AUTOSAR XML (schema 00050)
package /MICROSAR/NvM_swc/DataTypes
  impl type NvM_RequestResultType: compu {0=NVM_REQ_OK, 1=NVM_REQ_NOT_OK, 2=NVM_REQ_PENDING, 3=NVM_REQ_INTEGRITY_FAILED, 4=NVM_REQ_BLOCK_SKIPPED, 5=NVM_REQ_NV_INVALIDATED, 6=NVM_REQ_CANCELED, 7=NVM_REQ_REDUNDANCY_FAILED, 8=NVM_REQ_RESTORED_FROM_ROM}, range raw 0..8, implementation-data-type=uint8
  impl type NvM_BlockIdType: range raw 1..32767, implementation-data-type=uint16
package /MICROSAR/NvM_swc/Interfaces
  client server interface NvMAdministration: is-service=true, service-kind=NON-VOLATILE-RAM-MANAGER
    operation SetBlockProtection: possible-error=NvMAdministration/E_NOT_OK
      arg ProtectionEnabled: type=boolean, direction=IN
    error E_NOT_OK: error-code=1
  client server interface NvMService_AC3_SRBS: is-service=true, service-kind=NON-VOLATILE-RAM-MANAGER
    6 x operation, all with possible-error=NvMService_AC3_SRBS/E_NOT_OK:
      GetErrorStatus
        arg ErrorStatus: type=NvM_RequestResultType, direction=OUT
      SetRamBlockStatus
        arg RamBlockStatus: type=boolean, direction=IN
      ReadBlock
        arg DstPtr: type=dtRef_VOID, direction=IN
      WriteBlock
        arg SrcPtr: type=dtRef_const_VOID, direction=IN
      InvalidateNvBlock
      EraseBlock
    error E_NOT_OK: error-code=1
package /MICROSAR/NvM_swc/ComponentTypes
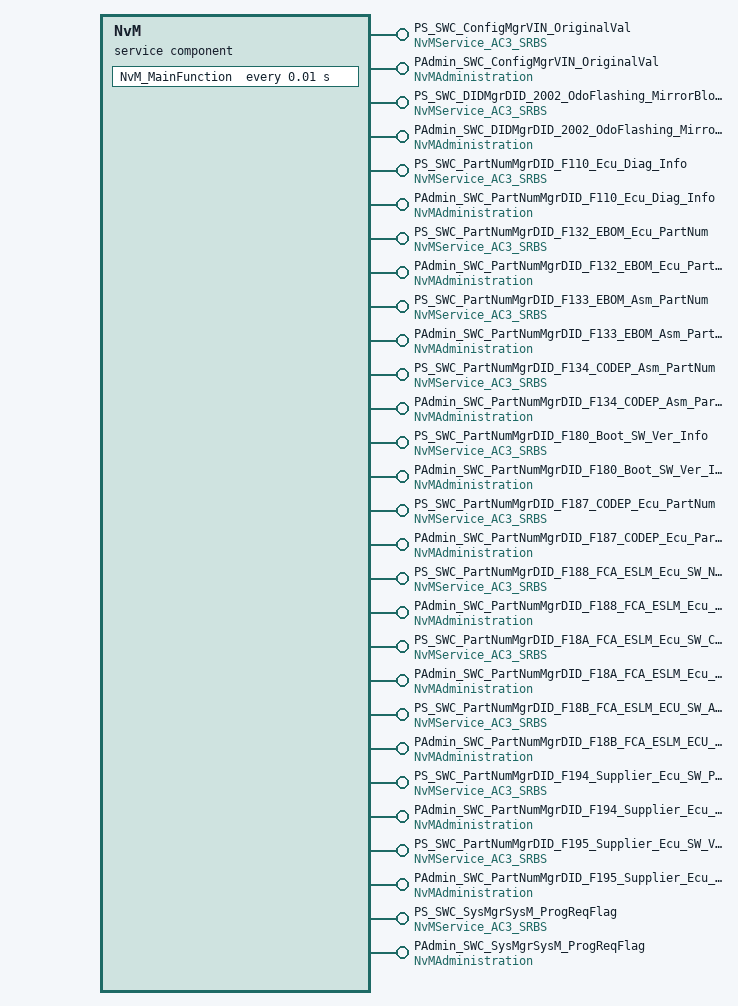
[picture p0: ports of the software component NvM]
  service sw component type NvM: category=SERVICE_COMPONENT
    28 x provide port:
      PS_SWC_ConfigMgrVIN_OriginalVal: provided-interface=NvMService_AC3_SRBS
      PAdmin_SWC_ConfigMgrVIN_OriginalVal: provided-interface=NvMAdministration
      PS_SWC_DIDMgrDID_2002_OdoFlashing_MirrorBlock: provided-interface=NvMService_AC3_SRBS
      PAdmin_SWC_DIDMgrDID_2002_OdoFlashing_MirrorBlock: provided-interface=NvMAdministration
      PS_SWC_PartNumMgrDID_F110_Ecu_Diag_Info: provided-interface=NvMService_AC3_SRBS
      PAdmin_SWC_PartNumMgrDID_F110_Ecu_Diag_Info: provided-interface=NvMAdministration
      PS_SWC_PartNumMgrDID_F132_EBOM_Ecu_PartNum: provided-interface=NvMService_AC3_SRBS
      PAdmin_SWC_PartNumMgrDID_F132_EBOM_Ecu_PartNum: provided-interface=NvMAdministration
      PS_SWC_PartNumMgrDID_F133_EBOM_Asm_PartNum: provided-interface=NvMService_AC3_SRBS
      PAdmin_SWC_PartNumMgrDID_F133_EBOM_Asm_PartNum: provided-interface=NvMAdministration
      PS_SWC_PartNumMgrDID_F134_CODEP_Asm_PartNum: provided-interface=NvMService_AC3_SRBS
      PAdmin_SWC_PartNumMgrDID_F134_CODEP_Asm_PartNum: provided-interface=NvMAdministration
      PS_SWC_PartNumMgrDID_F180_Boot_SW_Ver_Info: provided-interface=NvMService_AC3_SRBS
      PAdmin_SWC_PartNumMgrDID_F180_Boot_SW_Ver_Info: provided-interface=NvMAdministration
      PS_SWC_PartNumMgrDID_F187_CODEP_Ecu_PartNum: provided-interface=NvMService_AC3_SRBS
      PAdmin_SWC_PartNumMgrDID_F187_CODEP_Ecu_PartNum: provided-interface=NvMAdministration
      PS_SWC_PartNumMgrDID_F188_FCA_ESLM_Ecu_SW_Num: provided-interface=NvMService_AC3_SRBS
      PAdmin_SWC_PartNumMgrDID_F188_FCA_ESLM_Ecu_SW_Num: provided-interface=NvMAdministration
      PS_SWC_PartNumMgrDID_F18A_FCA_ESLM_Ecu_SW_Cal_Num: provided-interface=NvMService_AC3_SRBS
      PAdmin_SWC_PartNumMgrDID_F18A_FCA_ESLM_Ecu_SW_Cal_Num: provided-interface=NvMAdministration
      PS_SWC_PartNumMgrDID_F18B_FCA_ESLM_ECU_SW_App_Num: provided-interface=NvMService_AC3_SRBS
      PAdmin_SWC_PartNumMgrDID_F18B_FCA_ESLM_ECU_SW_App_Num: provided-interface=NvMAdministration
      PS_SWC_PartNumMgrDID_F194_Supplier_Ecu_SW_PartNum: provided-interface=NvMService_AC3_SRBS
      PAdmin_SWC_PartNumMgrDID_F194_Supplier_Ecu_SW_PartNum: provided-interface=NvMAdministration
      PS_SWC_PartNumMgrDID_F195_Supplier_Ecu_SW_VerNum: provided-interface=NvMService_AC3_SRBS
      PAdmin_SWC_PartNumMgrDID_F195_Supplier_Ecu_SW_VerNum: provided-interface=NvMAdministration
      PS_SWC_SysMgrSysM_ProgReqFlag: provided-interface=NvMService_AC3_SRBS
      PAdmin_SWC_SysMgrSysM_ProgReqFlag: provided-interface=NvMAdministration
    behavior NvMInternalBehavior: handle-termination-and-restart=NO-SUPPORT
      timing event Timer_NvM_MainFunction: start-on-event=NvM_MainFunction, period=0.01
      98 x operation invoked event:
        OpEventGetErrorStatus_GetErrorStatus_PS_SWC_ConfigMgrVIN_OriginalVal: start-on-event=GetErrorStatus, operation=PS_SWC_ConfigMgrVIN_OriginalVal.GetErrorStatus
        OpEventGetErrorStatus_GetErrorStatus_PS_SWC_DIDMgrDID_2002_OdoFlashing_MirrorBlock: start-on-event=GetErrorStatus, operation=PS_SWC_DIDMgrDID_2002_OdoFlashing_MirrorBlock.GetErrorStatus
        OpEventGetErrorStatus_GetErrorStatus_PS_SWC_PartNumMgrDID_F110_Ecu_Diag_Info: start-on-event=GetErrorStatus, operation=PS_SWC_PartNumMgrDID_F110_Ecu_Diag_Info.GetErrorStatus
        OpEventGetErrorStatus_GetErrorStatus_PS_SWC_PartNumMgrDID_F132_EBOM_Ecu_PartNum: start-on-event=GetErrorStatus, operation=PS_SWC_PartNumMgrDID_F132_EBOM_Ecu_PartNum.GetErrorStatus
        OpEventGetErrorStatus_GetErrorStatus_PS_SWC_PartNumMgrDID_F133_EBOM_Asm_PartNum: start-on-event=GetErrorStatus, operation=PS_SWC_PartNumMgrDID_F133_EBOM_Asm_PartNum.GetErrorStatus
        OpEventGetErrorStatus_GetErrorStatus_PS_SWC_PartNumMgrDID_F134_CODEP_Asm_PartNum: start-on-event=GetErrorStatus, operation=PS_SWC_PartNumMgrDID_F134_CODEP_Asm_PartNum.GetErrorStatus
        OpEventGetErrorStatus_GetErrorStatus_PS_SWC_PartNumMgrDID_F180_Boot_SW_Ver_Info: start-on-event=GetErrorStatus, operation=PS_SWC_PartNumMgrDID_F180_Boot_SW_Ver_Info.GetErrorStatus
        OpEventGetErrorStatus_GetErrorStatus_PS_SWC_PartNumMgrDID_F187_CODEP_Ecu_PartNum: start-on-event=GetErrorStatus, operation=PS_SWC_PartNumMgrDID_F187_CODEP_Ecu_PartNum.GetErrorStatus
        OpEventGetErrorStatus_GetErrorStatus_PS_SWC_PartNumMgrDID_F188_FCA_ESLM_Ecu_SW_Num: start-on-event=GetErrorStatus, operation=PS_SWC_PartNumMgrDID_F188_FCA_ESLM_Ecu_SW_Num.GetErrorStatus
        OpEventGetErrorStatus_GetErrorStatus_PS_SWC_PartNumMgrDID_F18A_FCA_ESLM_Ecu_SW_Cal_Num: start-on-event=GetErrorStatus, operation=PS_SWC_PartNumMgrDID_F18A_FCA_ESLM_Ecu_SW_Cal_Num.GetErrorStatus
        OpEventGetErrorStatus_GetErrorStatus_PS_SWC_PartNumMgrDID_F18B_FCA_ESLM_ECU_SW_App_Num: start-on-event=GetErrorStatus, operation=PS_SWC_PartNumMgrDID_F18B_FCA_ESLM_ECU_SW_App_Num.GetErrorStatus
        OpEventGetErrorStatus_GetErrorStatus_PS_SWC_PartNumMgrDID_F194_Supplier_Ecu_SW_PartNum: start-on-event=GetErrorStatus, operation=PS_SWC_PartNumMgrDID_F194_Supplier_Ecu_SW_PartNum.GetErrorStatus
        OpEventGetErrorStatus_GetErrorStatus_PS_SWC_PartNumMgrDID_F195_Supplier_Ecu_SW_VerNum: start-on-event=GetErrorStatus, operation=PS_SWC_PartNumMgrDID_F195_Supplier_Ecu_SW_VerNum.GetErrorStatus
        OpEventGetErrorStatus_GetErrorStatus_PS_SWC_SysMgrSysM_ProgReqFlag: start-on-event=GetErrorStatus, operation=PS_SWC_SysMgrSysM_ProgReqFlag.GetErrorStatus
        OpEventSetRamBlockStatus_SetRamBlockStatus_PS_SWC_ConfigMgrVIN_OriginalVal: start-on-event=SetRamBlockStatus, operation=PS_SWC_ConfigMgrVIN_OriginalVal.SetRamBlockStatus
        OpEventSetRamBlockStatus_SetRamBlockStatus_PS_SWC_DIDMgrDID_2002_OdoFlashing_MirrorBlock: start-on-event=SetRamBlockStatus, operation=PS_SWC_DIDMgrDID_2002_OdoFlashing_MirrorBlock.SetRamBlockStatus
        OpEventSetRamBlockStatus_SetRamBlockStatus_PS_SWC_PartNumMgrDID_F110_Ecu_Diag_Info: start-on-event=SetRamBlockStatus, operation=PS_SWC_PartNumMgrDID_F110_Ecu_Diag_Info.SetRamBlockStatus
        OpEventSetRamBlockStatus_SetRamBlockStatus_PS_SWC_PartNumMgrDID_F132_EBOM_Ecu_PartNum: start-on-event=SetRamBlockStatus, operation=PS_SWC_PartNumMgrDID_F132_EBOM_Ecu_PartNum.SetRamBlockStatus
        OpEventSetRamBlockStatus_SetRamBlockStatus_PS_SWC_PartNumMgrDID_F133_EBOM_Asm_PartNum: start-on-event=SetRamBlockStatus, operation=PS_SWC_PartNumMgrDID_F133_EBOM_Asm_PartNum.SetRamBlockStatus
        OpEventSetRamBlockStatus_SetRamBlockStatus_PS_SWC_PartNumMgrDID_F134_CODEP_Asm_PartNum: start-on-event=SetRamBlockStatus, operation=PS_SWC_PartNumMgrDID_F134_CODEP_Asm_PartNum.SetRamBlockStatus
        OpEventSetRamBlockStatus_SetRamBlockStatus_PS_SWC_PartNumMgrDID_F180_Boot_SW_Ver_Info: start-on-event=SetRamBlockStatus, operation=PS_SWC_PartNumMgrDID_F180_Boot_SW_Ver_Info.SetRamBlockStatus
        OpEventSetRamBlockStatus_SetRamBlockStatus_PS_SWC_PartNumMgrDID_F187_CODEP_Ecu_PartNum: start-on-event=SetRamBlockStatus, operation=PS_SWC_PartNumMgrDID_F187_CODEP_Ecu_PartNum.SetRamBlockStatus
        OpEventSetRamBlockStatus_SetRamBlockStatus_PS_SWC_PartNumMgrDID_F188_FCA_ESLM_Ecu_SW_Num: start-on-event=SetRamBlockStatus, operation=PS_SWC_PartNumMgrDID_F188_FCA_ESLM_Ecu_SW_Num.SetRamBlockStatus
        OpEventSetRamBlockStatus_SetRamBlockStatus_PS_SWC_PartNumMgrDID_F18A_FCA_ESLM_Ecu_SW_Cal_Num: start-on-event=SetRamBlockStatus, operation=PS_SWC_PartNumMgrDID_F18A_FCA_ESLM_Ecu_SW_Cal_Num.SetRamBlockStatus
        OpEventSetRamBlockStatus_SetRamBlockStatus_PS_SWC_PartNumMgrDID_F18B_FCA_ESLM_ECU_SW_App_Num: start-on-event=SetRamBlockStatus, operation=PS_SWC_PartNumMgrDID_F18B_FCA_ESLM_ECU_SW_App_Num.SetRamBlockStatus
        OpEventSetRamBlockStatus_SetRamBlockStatus_PS_SWC_PartNumMgrDID_F194_Supplier_Ecu_SW_PartNum: start-on-event=SetRamBlockStatus, operation=PS_SWC_PartNumMgrDID_F194_Supplier_Ecu_SW_PartNum.SetRamBlockStatus
        OpEventSetRamBlockStatus_SetRamBlockStatus_PS_SWC_PartNumMgrDID_F195_Supplier_Ecu_SW_VerNum: start-on-event=SetRamBlockStatus, operation=PS_SWC_PartNumMgrDID_F195_Supplier_Ecu_SW_VerNum.SetRamBlockStatus
        OpEventSetRamBlockStatus_SetRamBlockStatus_PS_SWC_SysMgrSysM_ProgReqFlag: start-on-event=SetRamBlockStatus, operation=PS_SWC_SysMgrSysM_ProgReqFlag.SetRamBlockStatus
        OpEventReadBlock_ReadBlock_PS_SWC_ConfigMgrVIN_OriginalVal: start-on-event=ReadBlock, operation=PS_SWC_ConfigMgrVIN_OriginalVal.ReadBlock
        OpEventReadBlock_ReadBlock_PS_SWC_DIDMgrDID_2002_OdoFlashing_MirrorBlock: start-on-event=ReadBlock, operation=PS_SWC_DIDMgrDID_2002_OdoFlashing_MirrorBlock.ReadBlock
        OpEventReadBlock_ReadBlock_PS_SWC_PartNumMgrDID_F110_Ecu_Diag_Info: start-on-event=ReadBlock, operation=PS_SWC_PartNumMgrDID_F110_Ecu_Diag_Info.ReadBlock
        OpEventReadBlock_ReadBlock_PS_SWC_PartNumMgrDID_F132_EBOM_Ecu_PartNum: start-on-event=ReadBlock, operation=PS_SWC_PartNumMgrDID_F132_EBOM_Ecu_PartNum.ReadBlock
        OpEventReadBlock_ReadBlock_PS_SWC_PartNumMgrDID_F133_EBOM_Asm_PartNum: start-on-event=ReadBlock, operation=PS_SWC_PartNumMgrDID_F133_EBOM_Asm_PartNum.ReadBlock
        OpEventReadBlock_ReadBlock_PS_SWC_PartNumMgrDID_F134_CODEP_Asm_PartNum: start-on-event=ReadBlock, operation=PS_SWC_PartNumMgrDID_F134_CODEP_Asm_PartNum.ReadBlock
        OpEventReadBlock_ReadBlock_PS_SWC_PartNumMgrDID_F180_Boot_SW_Ver_Info: start-on-event=ReadBlock, operation=PS_SWC_PartNumMgrDID_F180_Boot_SW_Ver_Info.ReadBlock
        OpEventReadBlock_ReadBlock_PS_SWC_PartNumMgrDID_F187_CODEP_Ecu_PartNum: start-on-event=ReadBlock, operation=PS_SWC_PartNumMgrDID_F187_CODEP_Ecu_PartNum.ReadBlock
        OpEventReadBlock_ReadBlock_PS_SWC_PartNumMgrDID_F188_FCA_ESLM_Ecu_SW_Num: start-on-event=ReadBlock, operation=PS_SWC_PartNumMgrDID_F188_FCA_ESLM_Ecu_SW_Num.ReadBlock
        OpEventReadBlock_ReadBlock_PS_SWC_PartNumMgrDID_F18A_FCA_ESLM_Ecu_SW_Cal_Num: start-on-event=ReadBlock, operation=PS_SWC_PartNumMgrDID_F18A_FCA_ESLM_Ecu_SW_Cal_Num.ReadBlock
        OpEventReadBlock_ReadBlock_PS_SWC_PartNumMgrDID_F18B_FCA_ESLM_ECU_SW_App_Num: start-on-event=ReadBlock, operation=PS_SWC_PartNumMgrDID_F18B_FCA_ESLM_ECU_SW_App_Num.ReadBlock
        OpEventReadBlock_ReadBlock_PS_SWC_PartNumMgrDID_F194_Supplier_Ecu_SW_PartNum: start-on-event=ReadBlock, operation=PS_SWC_PartNumMgrDID_F194_Supplier_Ecu_SW_PartNum.ReadBlock
        OpEventReadBlock_ReadBlock_PS_SWC_PartNumMgrDID_F195_Supplier_Ecu_SW_VerNum: start-on-event=ReadBlock, operation=PS_SWC_PartNumMgrDID_F195_Supplier_Ecu_SW_VerNum.ReadBlock
        OpEventReadBlock_ReadBlock_PS_SWC_SysMgrSysM_ProgReqFlag: start-on-event=ReadBlock, operation=PS_SWC_SysMgrSysM_ProgReqFlag.ReadBlock
        OpEventWriteBlock_WriteBlock_PS_SWC_ConfigMgrVIN_OriginalVal: start-on-event=WriteBlock, operation=PS_SWC_ConfigMgrVIN_OriginalVal.WriteBlock
        OpEventWriteBlock_WriteBlock_PS_SWC_DIDMgrDID_2002_OdoFlashing_MirrorBlock: start-on-event=WriteBlock, operation=PS_SWC_DIDMgrDID_2002_OdoFlashing_MirrorBlock.WriteBlock
        OpEventWriteBlock_WriteBlock_PS_SWC_PartNumMgrDID_F110_Ecu_Diag_Info: start-on-event=WriteBlock, operation=PS_SWC_PartNumMgrDID_F110_Ecu_Diag_Info.WriteBlock
        OpEventWriteBlock_WriteBlock_PS_SWC_PartNumMgrDID_F132_EBOM_Ecu_PartNum: start-on-event=WriteBlock, operation=PS_SWC_PartNumMgrDID_F132_EBOM_Ecu_PartNum.WriteBlock
        OpEventWriteBlock_WriteBlock_PS_SWC_PartNumMgrDID_F133_EBOM_Asm_PartNum: start-on-event=WriteBlock, operation=PS_SWC_PartNumMgrDID_F133_EBOM_Asm_PartNum.WriteBlock
        OpEventWriteBlock_WriteBlock_PS_SWC_PartNumMgrDID_F134_CODEP_Asm_PartNum: start-on-event=WriteBlock, operation=PS_SWC_PartNumMgrDID_F134_CODEP_Asm_PartNum.WriteBlock
        OpEventWriteBlock_WriteBlock_PS_SWC_PartNumMgrDID_F180_Boot_SW_Ver_Info: start-on-event=WriteBlock, operation=PS_SWC_PartNumMgrDID_F180_Boot_SW_Ver_Info.WriteBlock
        OpEventWriteBlock_WriteBlock_PS_SWC_PartNumMgrDID_F187_CODEP_Ecu_PartNum: start-on-event=WriteBlock, operation=PS_SWC_PartNumMgrDID_F187_CODEP_Ecu_PartNum.WriteBlock
        OpEventWriteBlock_WriteBlock_PS_SWC_PartNumMgrDID_F188_FCA_ESLM_Ecu_SW_Num: start-on-event=WriteBlock, operation=PS_SWC_PartNumMgrDID_F188_FCA_ESLM_Ecu_SW_Num.WriteBlock
        OpEventWriteBlock_WriteBlock_PS_SWC_PartNumMgrDID_F18A_FCA_ESLM_Ecu_SW_Cal_Num: start-on-event=WriteBlock, operation=PS_SWC_PartNumMgrDID_F18A_FCA_ESLM_Ecu_SW_Cal_Num.WriteBlock
        OpEventWriteBlock_WriteBlock_PS_SWC_PartNumMgrDID_F18B_FCA_ESLM_ECU_SW_App_Num: start-on-event=WriteBlock, operation=PS_SWC_PartNumMgrDID_F18B_FCA_ESLM_ECU_SW_App_Num.WriteBlock
        OpEventWriteBlock_WriteBlock_PS_SWC_PartNumMgrDID_F194_Supplier_Ecu_SW_PartNum: start-on-event=WriteBlock, operation=PS_SWC_PartNumMgrDID_F194_Supplier_Ecu_SW_PartNum.WriteBlock
        OpEventWriteBlock_WriteBlock_PS_SWC_PartNumMgrDID_F195_Supplier_Ecu_SW_VerNum: start-on-event=WriteBlock, operation=PS_SWC_PartNumMgrDID_F195_Supplier_Ecu_SW_VerNum.WriteBlock
        OpEventWriteBlock_WriteBlock_PS_SWC_SysMgrSysM_ProgReqFlag: start-on-event=WriteBlock, operation=PS_SWC_SysMgrSysM_ProgReqFlag.WriteBlock
        OpEventInvalidateNvBlock_InvalidateNvBlock_PS_SWC_ConfigMgrVIN_OriginalVal: start-on-event=InvalidateNvBlock, operation=PS_SWC_ConfigMgrVIN_OriginalVal.InvalidateNvBlock
        OpEventInvalidateNvBlock_InvalidateNvBlock_PS_SWC_DIDMgrDID_2002_OdoFlashing_MirrorBlock: start-on-event=InvalidateNvBlock, operation=PS_SWC_DIDMgrDID_2002_OdoFlashing_MirrorBlock.InvalidateNvBlock
        OpEventInvalidateNvBlock_InvalidateNvBlock_PS_SWC_PartNumMgrDID_F110_Ecu_Diag_Info: start-on-event=InvalidateNvBlock, operation=PS_SWC_PartNumMgrDID_F110_Ecu_Diag_Info.InvalidateNvBlock
        OpEventInvalidateNvBlock_InvalidateNvBlock_PS_SWC_PartNumMgrDID_F132_EBOM_Ecu_PartNum: start-on-event=InvalidateNvBlock, operation=PS_SWC_PartNumMgrDID_F132_EBOM_Ecu_PartNum.InvalidateNvBlock
        OpEventInvalidateNvBlock_InvalidateNvBlock_PS_SWC_PartNumMgrDID_F133_EBOM_Asm_PartNum: start-on-event=InvalidateNvBlock, operation=PS_SWC_PartNumMgrDID_F133_EBOM_Asm_PartNum.InvalidateNvBlock
        OpEventInvalidateNvBlock_InvalidateNvBlock_PS_SWC_PartNumMgrDID_F134_CODEP_Asm_PartNum: start-on-event=InvalidateNvBlock, operation=PS_SWC_PartNumMgrDID_F134_CODEP_Asm_PartNum.InvalidateNvBlock
        OpEventInvalidateNvBlock_InvalidateNvBlock_PS_SWC_PartNumMgrDID_F180_Boot_SW_Ver_Info: start-on-event=InvalidateNvBlock, operation=PS_SWC_PartNumMgrDID_F180_Boot_SW_Ver_Info.InvalidateNvBlock
        OpEventInvalidateNvBlock_InvalidateNvBlock_PS_SWC_PartNumMgrDID_F187_CODEP_Ecu_PartNum: start-on-event=InvalidateNvBlock, operation=PS_SWC_PartNumMgrDID_F187_CODEP_Ecu_PartNum.InvalidateNvBlock
        OpEventInvalidateNvBlock_InvalidateNvBlock_PS_SWC_PartNumMgrDID_F188_FCA_ESLM_Ecu_SW_Num: start-on-event=InvalidateNvBlock, operation=PS_SWC_PartNumMgrDID_F188_FCA_ESLM_Ecu_SW_Num.InvalidateNvBlock
        OpEventInvalidateNvBlock_InvalidateNvBlock_PS_SWC_PartNumMgrDID_F18A_FCA_ESLM_Ecu_SW_Cal_Num: start-on-event=InvalidateNvBlock, operation=PS_SWC_PartNumMgrDID_F18A_FCA_ESLM_Ecu_SW_Cal_Num.InvalidateNvBlock
        OpEventInvalidateNvBlock_InvalidateNvBlock_PS_SWC_PartNumMgrDID_F18B_FCA_ESLM_ECU_SW_App_Num: start-on-event=InvalidateNvBlock, operation=PS_SWC_PartNumMgrDID_F18B_FCA_ESLM_ECU_SW_App_Num.InvalidateNvBlock
        OpEventInvalidateNvBlock_InvalidateNvBlock_PS_SWC_PartNumMgrDID_F194_Supplier_Ecu_SW_PartNum: start-on-event=InvalidateNvBlock, operation=PS_SWC_PartNumMgrDID_F194_Supplier_Ecu_SW_PartNum.InvalidateNvBlock
        OpEventInvalidateNvBlock_InvalidateNvBlock_PS_SWC_PartNumMgrDID_F195_Supplier_Ecu_SW_VerNum: start-on-event=InvalidateNvBlock, operation=PS_SWC_PartNumMgrDID_F195_Supplier_Ecu_SW_VerNum.InvalidateNvBlock
        OpEventInvalidateNvBlock_InvalidateNvBlock_PS_SWC_SysMgrSysM_ProgReqFlag: start-on-event=InvalidateNvBlock, operation=PS_SWC_SysMgrSysM_ProgReqFlag.InvalidateNvBlock
        OpEventEraseBlock_EraseBlock_PS_SWC_ConfigMgrVIN_OriginalVal: start-on-event=EraseBlock, operation=PS_SWC_ConfigMgrVIN_OriginalVal.EraseBlock
        OpEventEraseBlock_EraseBlock_PS_SWC_DIDMgrDID_2002_OdoFlashing_MirrorBlock: start-on-event=EraseBlock, operation=PS_SWC_DIDMgrDID_2002_OdoFlashing_MirrorBlock.EraseBlock
        OpEventEraseBlock_EraseBlock_PS_SWC_PartNumMgrDID_F110_Ecu_Diag_Info: start-on-event=EraseBlock, operation=PS_SWC_PartNumMgrDID_F110_Ecu_Diag_Info.EraseBlock
        OpEventEraseBlock_EraseBlock_PS_SWC_PartNumMgrDID_F132_EBOM_Ecu_PartNum: start-on-event=EraseBlock, operation=PS_SWC_PartNumMgrDID_F132_EBOM_Ecu_PartNum.EraseBlock
        OpEventEraseBlock_EraseBlock_PS_SWC_PartNumMgrDID_F133_EBOM_Asm_PartNum: start-on-event=EraseBlock, operation=PS_SWC_PartNumMgrDID_F133_EBOM_Asm_PartNum.EraseBlock
        OpEventEraseBlock_EraseBlock_PS_SWC_PartNumMgrDID_F134_CODEP_Asm_PartNum: start-on-event=EraseBlock, operation=PS_SWC_PartNumMgrDID_F134_CODEP_Asm_PartNum.EraseBlock
        OpEventEraseBlock_EraseBlock_PS_SWC_PartNumMgrDID_F180_Boot_SW_Ver_Info: start-on-event=EraseBlock, operation=PS_SWC_PartNumMgrDID_F180_Boot_SW_Ver_Info.EraseBlock
        OpEventEraseBlock_EraseBlock_PS_SWC_PartNumMgrDID_F187_CODEP_Ecu_PartNum: start-on-event=EraseBlock, operation=PS_SWC_PartNumMgrDID_F187_CODEP_Ecu_PartNum.EraseBlock
        OpEventEraseBlock_EraseBlock_PS_SWC_PartNumMgrDID_F188_FCA_ESLM_Ecu_SW_Num: start-on-event=EraseBlock, operation=PS_SWC_PartNumMgrDID_F188_FCA_ESLM_Ecu_SW_Num.EraseBlock
        OpEventEraseBlock_EraseBlock_PS_SWC_PartNumMgrDID_F18A_FCA_ESLM_Ecu_SW_Cal_Num: start-on-event=EraseBlock, operation=PS_SWC_PartNumMgrDID_F18A_FCA_ESLM_Ecu_SW_Cal_Num.EraseBlock
        OpEventEraseBlock_EraseBlock_PS_SWC_PartNumMgrDID_F18B_FCA_ESLM_ECU_SW_App_Num: start-on-event=EraseBlock, operation=PS_SWC_PartNumMgrDID_F18B_FCA_ESLM_ECU_SW_App_Num.EraseBlock
        OpEventEraseBlock_EraseBlock_PS_SWC_PartNumMgrDID_F194_Supplier_Ecu_SW_PartNum: start-on-event=EraseBlock, operation=PS_SWC_PartNumMgrDID_F194_Supplier_Ecu_SW_PartNum.EraseBlock
        OpEventEraseBlock_EraseBlock_PS_SWC_PartNumMgrDID_F195_Supplier_Ecu_SW_VerNum: start-on-event=EraseBlock, operation=PS_SWC_PartNumMgrDID_F195_Supplier_Ecu_SW_VerNum.EraseBlock
        OpEventEraseBlock_EraseBlock_PS_SWC_SysMgrSysM_ProgReqFlag: start-on-event=EraseBlock, operation=PS_SWC_SysMgrSysM_ProgReqFlag.EraseBlock
        OpEventSetBlockProtection_SetBlockProtection_PAdmin_SWC_ConfigMgrVIN_OriginalVal: start-on-event=SetBlockProtection, operation=PAdmin_SWC_ConfigMgrVIN_OriginalVal.SetBlockProtection
        OpEventSetBlockProtection_SetBlockProtection_PAdmin_SWC_DIDMgrDID_2002_OdoFlashing_MirrorBlock: start-on-event=SetBlockProtection, operation=PAdmin_SWC_DIDMgrDID_2002_OdoFlashing_MirrorBlock.SetBlockProtection
        OpEventSetBlockProtection_SetBlockProtection_PAdmin_SWC_PartNumMgrDID_F110_Ecu_Diag_Info: start-on-event=SetBlockProtection, operation=PAdmin_SWC_PartNumMgrDID_F110_Ecu_Diag_Info.SetBlockProtection
        OpEventSetBlockProtection_SetBlockProtection_PAdmin_SWC_PartNumMgrDID_F132_EBOM_Ecu_PartNum: start-on-event=SetBlockProtection, operation=PAdmin_SWC_PartNumMgrDID_F132_EBOM_Ecu_PartNum.SetBlockProtection
        OpEventSetBlockProtection_SetBlockProtection_PAdmin_SWC_PartNumMgrDID_F133_EBOM_Asm_PartNum: start-on-event=SetBlockProtection, operation=PAdmin_SWC_PartNumMgrDID_F133_EBOM_Asm_PartNum.SetBlockProtection
        OpEventSetBlockProtection_SetBlockProtection_PAdmin_SWC_PartNumMgrDID_F134_CODEP_Asm_PartNum: start-on-event=SetBlockProtection, operation=PAdmin_SWC_PartNumMgrDID_F134_CODEP_Asm_PartNum.SetBlockProtection
        OpEventSetBlockProtection_SetBlockProtection_PAdmin_SWC_PartNumMgrDID_F180_Boot_SW_Ver_Info: start-on-event=SetBlockProtection, operation=PAdmin_SWC_PartNumMgrDID_F180_Boot_SW_Ver_Info.SetBlockProtection
        OpEventSetBlockProtection_SetBlockProtection_PAdmin_SWC_PartNumMgrDID_F187_CODEP_Ecu_PartNum: start-on-event=SetBlockProtection, operation=PAdmin_SWC_PartNumMgrDID_F187_CODEP_Ecu_PartNum.SetBlockProtection
        OpEventSetBlockProtection_SetBlockProtection_PAdmin_SWC_PartNumMgrDID_F188_FCA_ESLM_Ecu_SW_Num: start-on-event=SetBlockProtection, operation=PAdmin_SWC_PartNumMgrDID_F188_FCA_ESLM_Ecu_SW_Num.SetBlockProtection
        OpEventSetBlockProtection_SetBlockProtection_PAdmin_SWC_PartNumMgrDID_F18A_FCA_ESLM_Ecu_SW_Cal_Num: start-on-event=SetBlockProtection, operation=PAdmin_SWC_PartNumMgrDID_F18A_FCA_ESLM_Ecu_SW_Cal_Num.SetBlockProtection
        OpEventSetBlockProtection_SetBlockProtection_PAdmin_SWC_PartNumMgrDID_F18B_FCA_ESLM_ECU_SW_App_Num: start-on-event=SetBlockProtection, operation=PAdmin_SWC_PartNumMgrDID_F18B_FCA_ESLM_ECU_SW_App_Num.SetBlockProtection
        OpEventSetBlockProtection_SetBlockProtection_PAdmin_SWC_PartNumMgrDID_F194_Supplier_Ecu_SW_PartNum: start-on-event=SetBlockProtection, operation=PAdmin_SWC_PartNumMgrDID_F194_Supplier_Ecu_SW_PartNum.SetBlockProtection
        OpEventSetBlockProtection_SetBlockProtection_PAdmin_SWC_PartNumMgrDID_F195_Supplier_Ecu_SW_VerNum: start-on-event=SetBlockProtection, operation=PAdmin_SWC_PartNumMgrDID_F195_Supplier_Ecu_SW_VerNum.SetBlockProtection
        OpEventSetBlockProtection_SetBlockProtection_PAdmin_SWC_SysMgrSysM_ProgReqFlag: start-on-event=SetBlockProtection, operation=PAdmin_SWC_SysMgrSysM_ProgReqFlag.SetBlockProtection
      port-api-options:
        {enable-take-address=true, indirect-api=false, port-defined-argument-value{value=11, value-type=NvM_BlockIdType}, port=PS_SWC_PartNumMgrDID_F180_Boot_SW_Ver_Info}
        {enable-take-address=true, indirect-api=false, port-defined-argument-value{value=11, value-type=NvM_BlockIdType}, port=PAdmin_SWC_PartNumMgrDID_F180_Boot_SW_Ver_Info}
        {enable-take-address=true, indirect-api=false, port-defined-argument-value{value=3, value-type=NvM_BlockIdType}, port=PS_SWC_SysMgrSysM_ProgReqFlag}
        {enable-take-address=true, indirect-api=false, port-defined-argument-value{value=3, value-type=NvM_BlockIdType}, port=PAdmin_SWC_SysMgrSysM_ProgReqFlag}
        {enable-take-address=true, indirect-api=false, port-defined-argument-value{value=27, value-type=NvM_BlockIdType}, port=PS_SWC_ConfigMgrVIN_OriginalVal}
        {enable-take-address=true, indirect-api=false, port-defined-argument-value{value=27, value-type=NvM_BlockIdType}, port=PAdmin_SWC_ConfigMgrVIN_OriginalVal}
        {enable-take-address=true, indirect-api=false, port-defined-argument-value{value=26, value-type=NvM_BlockIdType}, port=PS_SWC_DIDMgrDID_2002_OdoFlashing_MirrorBlock}
        {enable-take-address=true, indirect-api=false, port-defined-argument-value{value=26, value-type=NvM_BlockIdType}, port=PAdmin_SWC_DIDMgrDID_2002_OdoFlashing_MirrorBlock}
        {enable-take-address=true, indirect-api=false, port-defined-argument-value{value=25, value-type=NvM_BlockIdType}, port=PS_SWC_PartNumMgrDID_F110_Ecu_Diag_Info}
        {enable-take-address=true, indirect-api=false, port-defined-argument-value{value=25, value-type=NvM_BlockIdType}, port=PAdmin_SWC_PartNumMgrDID_F110_Ecu_Diag_Info}
        {enable-take-address=true, indirect-api=false, port-defined-argument-value{value=22, value-type=NvM_BlockIdType}, port=PS_SWC_PartNumMgrDID_F132_EBOM_Ecu_PartNum}
        {enable-take-address=true, indirect-api=false, port-defined-argument-value{value=22, value-type=NvM_BlockIdType}, port=PAdmin_SWC_PartNumMgrDID_F132_EBOM_Ecu_PartNum}
        {enable-take-address=true, indirect-api=false, port-defined-argument-value{value=17, value-type=NvM_BlockIdType}, port=PS_SWC_PartNumMgrDID_F133_EBOM_Asm_PartNum}
        {enable-take-address=true, indirect-api=false, port-defined-argument-value{value=17, value-type=NvM_BlockIdType}, port=PAdmin_SWC_PartNumMgrDID_F133_EBOM_Asm_PartNum}
        {enable-take-address=true, indirect-api=false, port-defined-argument-value{value=21, value-type=NvM_BlockIdType}, port=PS_SWC_PartNumMgrDID_F134_CODEP_Asm_PartNum}
        {enable-take-address=true, indirect-api=false, port-defined-argument-value{value=21, value-type=NvM_BlockIdType}, port=PAdmin_SWC_PartNumMgrDID_F134_CODEP_Asm_PartNum}
        {enable-take-address=true, indirect-api=false, port-defined-argument-value{value=20, value-type=NvM_BlockIdType}, port=PS_SWC_PartNumMgrDID_F187_CODEP_Ecu_PartNum}
        {enable-take-address=true, indirect-api=false, port-defined-argument-value{value=20, value-type=NvM_BlockIdType}, port=PAdmin_SWC_PartNumMgrDID_F187_CODEP_Ecu_PartNum}
        {enable-take-address=true, indirect-api=false, port-defined-argument-value{value=16, value-type=NvM_BlockIdType}, port=PS_SWC_PartNumMgrDID_F188_FCA_ESLM_Ecu_SW_Num}
        {enable-take-address=true, indirect-api=false, port-defined-argument-value{value=16, value-type=NvM_BlockIdType}, port=PAdmin_SWC_PartNumMgrDID_F188_FCA_ESLM_Ecu_SW_Num}
        {enable-take-address=true, indirect-api=false, port-defined-argument-value{value=18, value-type=NvM_BlockIdType}, port=PS_SWC_PartNumMgrDID_F18A_FCA_ESLM_Ecu_SW_Cal_Num}
        {enable-take-address=true, indirect-api=false, port-defined-argument-value{value=18, value-type=NvM_BlockIdType}, port=PAdmin_SWC_PartNumMgrDID_F18A_FCA_ESLM_Ecu_SW_Cal_Num}
        {enable-take-address=true, indirect-api=false, port-defined-argument-value{value=19, value-type=NvM_BlockIdType}, port=PS_SWC_PartNumMgrDID_F18B_FCA_ESLM_ECU_SW_App_Num}
        {enable-take-address=true, indirect-api=false, port-defined-argument-value{value=19, value-type=NvM_BlockIdType}, port=PAdmin_SWC_PartNumMgrDID_F18B_FCA_ESLM_ECU_SW_App_Num}
        {enable-take-address=true, indirect-api=false, port-defined-argument-value{value=23, value-type=NvM_BlockIdType}, port=PS_SWC_PartNumMgrDID_F194_Supplier_Ecu_SW_PartNum}
        {enable-take-address=true, indirect-api=false, port-defined-argument-value{value=23, value-type=NvM_BlockIdType}, port=PAdmin_SWC_PartNumMgrDID_F194_Supplier_Ecu_SW_PartNum}
        {enable-take-address=true, indirect-api=false, port-defined-argument-value{value=24, value-type=NvM_BlockIdType}, port=PS_SWC_PartNumMgrDID_F195_Supplier_Ecu_SW_VerNum}
        {enable-take-address=true, indirect-api=false, port-defined-argument-value{value=24, value-type=NvM_BlockIdType}, port=PAdmin_SWC_PartNumMgrDID_F195_Supplier_Ecu_SW_VerNum}
      8 x runnable:
        NvM_MainFunction
        GetErrorStatus: can-be-invoked-concurrently=true, symbol=NvM_GetErrorStatus
        SetRamBlockStatus: can-be-invoked-concurrently=true, symbol=NvM_SetRamBlockStatus
        ReadBlock: can-be-invoked-concurrently=true, symbol=NvM_ReadBlock
        WriteBlock: can-be-invoked-concurrently=true, symbol=NvM_WriteBlock
        InvalidateNvBlock: can-be-invoked-concurrently=true, symbol=NvM_InvalidateNvBlock
        EraseBlock: can-be-invoked-concurrently=true, symbol=NvM_EraseNvBlock
        SetBlockProtection: can-be-invoked-concurrently=true, symbol=NvM_SetBlockProtection
  swc implementation NvMImplementation: programming-language=C, behavior=NvMInternalBehavior
